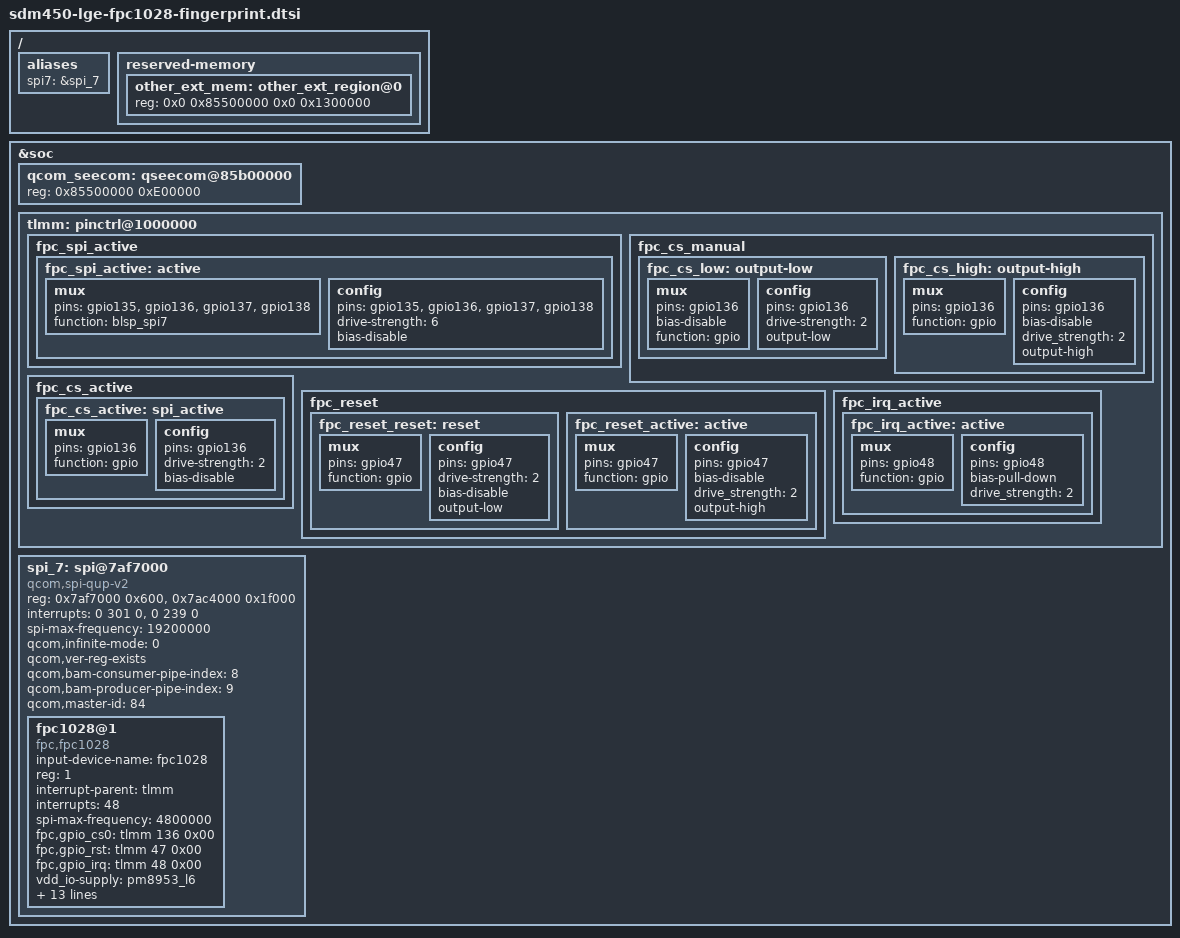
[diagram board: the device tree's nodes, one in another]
/*
 * Copyright (c) 2017, The Linux Foundation. All rights reserved.
 *
 * This program is free software; you can redistribute it and/or modify
 * it under the terms of the GNU General Public License version 2 and
 * only version 2 as published by the Free Software Foundation.
 *
 * This program is distributed in the hope that it will be useful,
 * but WITHOUT ANY WARRANTY; without even the implied warranty of
 * MERCHANTABILITY or FITNESS FOR A PARTICULAR PURPOSE.  See the
 * GNU General Public License for more details.
 */
/{
        aliases {
	        spi7 = &spi_7;
	};

	reserved-memory {
		other_ext_mem: other_ext_region@0 {
			reg = <0x0 0x85500000 0x0 0x1300000>;
		};
	};
};

&soc{
	qcom_seecom: qseecom@85b00000 {
		reg = <0x85500000 0xE00000>;
	};

	tlmm: pinctrl@1000000 {
		fpc_spi_active {
			fpc_spi_active: active {
				mux {
					pins = "gpio135", "gpio136", "gpio137", "gpio138";
					function = "blsp_spi7";
				};

				config {
					pins = "gpio135", "gpio136", "gpio137", "gpio138";
					drive-strength = <6>; /* 6 MA */
					bias-disable ; /* No PULL */
				};
			};
                 };

                 fpc_cs_manual{
			fpc_cs_low: output-low {
                                /* CS */
				mux {
					pins = "gpio136";
                    bias-disable;
					function = "gpio";
				};

				config {
					pins = "gpio136";
					drive-strength = <2>; /* 2 MA */
					output-low; /* output-low */
				};
			};
                        fpc_cs_high: output-high {
		                mux {
		                        pins = "gpio136";
		                        function = "gpio";
		                };

		                config {
		                       pins = "gpio136";
		                       bias-disable;
		                       drive_strength = <2>;
		                       output-high;
		                };
	               };
		 };
                 fpc_cs_active{
			fpc_cs_active: spi_active {
				mux {
					pins = "gpio136";
					function = "gpio";
				};

				config {
					pins = "gpio136";
					drive-strength = <2>;
					bias-disable;
				};
			};
                 };

                 fpc_reset{
			fpc_reset_reset: reset {
				mux {
					pins = "gpio47";
					function = "gpio";
				};

				config {
					pins = "gpio47";
					drive-strength = <2>;
					bias-disable;
                    output-low;
				};
			};
			fpc_reset_active: active {
				mux {
					pins = "gpio47";
					function = "gpio";
				};

				config {
					pins = "gpio47";
					bias-disable;
					drive_strength = <2>;
					output-high;
				};
			};
		 };

		 fpc_irq_active {
                        fpc_irq_active: active {
		                mux {
			                pins = "gpio48";
			                function = "gpio";
		                };

		                config {
			                pins = "gpio48";
			                bias-pull-down;
			                drive_strength = <2>;
		                };
		       };
	         };
        };

	spi_7: spi@7af7000 { /* BLSP7 */
		compatible = "qcom,spi-qup-v2";
		#address-cells = <1>;
		#size-cells = <0>;
		reg-names = "spi_physical", "spi_bam_physical";
		reg = <0x7af7000 0x600>,
			<0x7ac4000 0x1f000>;
		interrupt-names = "spi_irq", "spi_bam_irq";
		interrupts = <0 301 0>, <0 239 0>;
		spi-max-frequency = <19200000>;

	        qcom,infinite-mode = <0>;

		qcom,ver-reg-exists;
		qcom,bam-consumer-pipe-index = <8>;
		qcom,bam-producer-pipe-index = <9>;
		qcom,master-id = <84>;
	};
};

&spi_7 {

    fpc1028@1 {
		status = "ok";
		compatible = "fpc,fpc1028";
                input-device-name = "fpc1028";
		reg = <1>;

		interrupt-parent = <&tlmm>;
		interrupts = <48>;

		spi-max-frequency = <4800000>;

                fpc,gpio_cs0	= <&tlmm 136 0x00>;
                fpc,gpio_rst	= <&tlmm 47 0x00>;
                fpc,gpio_irq	= <&tlmm 48 0x00>;
                vdd_io-supply	= <&pm8953_l6>;

                fpc,use_fpc2050 = <1>;
		fpc,enable-on-boot;
		fpc,enable-wakeup;

		fpc,event-type = <4>;
		fpc,event-code = <4>;
		spi-qup-id = <7>;

		pinctrl-names = "fpc1028_spi_active",
		                "fpc1028_reset_reset",
		                "fpc1028_reset_active",
		                "fpc1028_cs_low",
		                "fpc1028_cs_high",
		                "fpc1028_cs_active",
		                "fpc1028_irq_active";

		pinctrl-0 = <&fpc_spi_active>;
		pinctrl-1 = <&fpc_reset_reset>;
		pinctrl-2 = <&fpc_reset_active>;
		pinctrl-3 = <&fpc_cs_low>;
		pinctrl-4 = <&fpc_cs_high>;
		pinctrl-5 = <&fpc_cs_active>;
		pinctrl-6 = <&fpc_irq_active>;
	};
};

